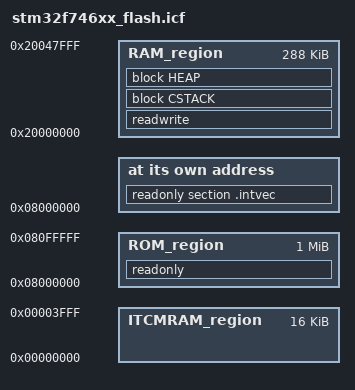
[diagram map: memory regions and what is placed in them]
/*###ICF### Section handled by ICF editor, don't touch! ****/
/*-Editor annotation file-*/
/* IcfEditorFile="$TOOLKIT_DIR$\config\ide\IcfEditor\cortex_v1_0.xml" */
/*-Specials-*/
define symbol __ICFEDIT_intvec_start__ = 0x08000000;
/*-Memory Regions-*/
define symbol __ICFEDIT_region_ROM_start__     = 0x08000000;
define symbol __ICFEDIT_region_ROM_end__       = 0x080FFFFF;
define symbol __ICFEDIT_region_RAM_start__     = 0x20000000;
/* RAM 末端收到 0x20047FFF：0x20048000 起是 lwIP 堆（MEM_SIZE=8192，见 lwipopts.h
   的 LWIP_RAM_HEAP_POINTER），0x2004C000 起是 LWIP/Target/ethernetif.c 用
   #pragma location 固定的 ETH DMA 描述符。这两块由 ETH 驱动独占，
   链接器不允许在其上分配，否则 DMA 与变量会互相覆盖。 */
define symbol __ICFEDIT_region_RAM_end__       = 0x20047FFF;
define symbol __ICFEDIT_region_ITCMRAM_start__ = 0x00000000;
define symbol __ICFEDIT_region_ITCMRAM_end__   = 0x00003FFF;
/*-Sizes-*/
define symbol __ICFEDIT_size_cstack__ = 0x400;
define symbol __ICFEDIT_size_heap__   = 0x200;
/**** End of ICF editor section. ###ICF###*/


define memory mem with size = 4G;
define region ROM_region      = mem:[from __ICFEDIT_region_ROM_start__   to __ICFEDIT_region_ROM_end__];
define region RAM_region      = mem:[from __ICFEDIT_region_RAM_start__   to __ICFEDIT_region_RAM_end__];
define region ITCMRAM_region  = mem:[from __ICFEDIT_region_ITCMRAM_start__ to __ICFEDIT_region_ITCMRAM_end__];

define block CSTACK    with alignment = 8, size = __ICFEDIT_size_cstack__   { };
define block HEAP      with alignment = 8, size = __ICFEDIT_size_heap__     { };

initialize by copy { readwrite };
do not initialize  { section .noinit };

place at address mem:__ICFEDIT_intvec_start__ { readonly section .intvec };

place in ROM_region   { readonly };
place in RAM_region   { readwrite,
                        block CSTACK, block HEAP };
